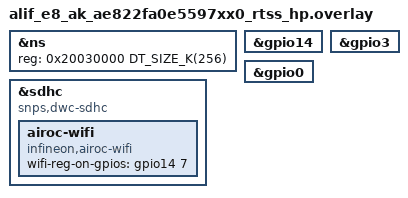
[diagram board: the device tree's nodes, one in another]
/*
 * Copyright (c) 2025 Alif Semiconductor.
 * SPDX-License-Identifier: Apache-2.0
 */

ns: &ns {
	reg = <0x20030000 DT_SIZE_K(256)>;
	status = "okay";
};

&gpio14 {
	status = "okay";
};

&gpio3 {
	status = "okay";
};

&gpio0 {
	status = "okay";
};


sdhc: &sdhc {
	compatible = "snps,dwc-sdhc";
	status = "okay";

	airoc-wifi {
		compatible = "infineon,airoc-wifi";
		status = "okay";

		/* Wi-Fi control gpios */
		wifi-reg-on-gpios    = <&gpio14 7 GPIO_ACTIVE_HIGH>;
	/*	wifi-host-wake-gpios = <&gpio0 1 GPIO_ACTIVE_LOW>; */
	/*	wifi-dev-wake-gpios  = <&gpio0 0 GPIO_ACTIVE_LOW>; */
	};
};
